# CEC1734_S0_2HW register map
Vendor: Microchip
Registers are 32-bit, read-write, reset 0x0 unless marked. A register's access mark holds for its fields unless they carry their own. Addresses are absolute, and some are shared; only a register's first bit layout is shown; [hi:lo] are bit positions; {n}, {i} and the like mark numbered series; 'fields as' and 'values as' point back to an identical list.

## SPI_MON0
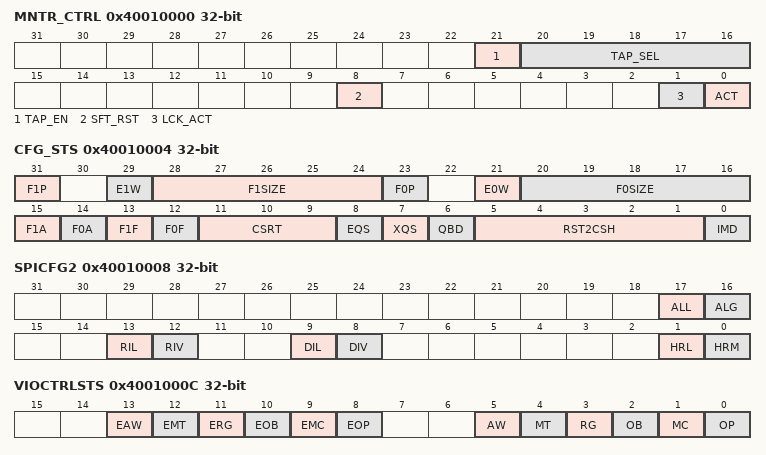
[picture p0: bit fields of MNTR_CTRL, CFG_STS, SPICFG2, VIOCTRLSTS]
0x40010000 MNTR_CTRL
  [21] TAP_EN — CPTR_CLK_TAP_EN enable the delay taps. It is recommended that a customer set the TAP_EN bit to 1, and the TAP_SEL field to 04h.
  [20:16] TAP_SEL — CPTR_CLK_TAP_SEL selects which 0.5ns delay tap to have the capture clock on. 00h = 0 ns delay (or if TAP_EN = 0). 01h = 0.5ns nom delay; +/- 50% 02h = 1.0ns 03h = 1.5ns 04h = 2.0ns etc. 1Fh = 15.5ns
  [8] SFT_RST — Soft Reset. This field is auto cleared by hardware. 1= Soft Reset SPI Monitor, 0 = No Effect
  [1] LCK_ACT — Lock Activate 1= Activate field Locked, 0= Activate field unlocked
  [0] ACT — Activate 1= Activate, 0= De-activate
0x40010004 CFG_STS
  [31] F1P — Flash 1 Present. 0=Not Present, 1=Present
  [29] E1W — Enable Wrap Detection. 0=Disable, 1=Enable
  [28:24] F1SIZE — Flash 1 Size. Flash sizes are expressed in bytes as a power of 2, matching a Flash Get-ID convention. For the most common cases: 17h = 23d => 2^23 = 8MByte 18h = 24d => 2^24 = 16MByte 19h = 25d => 2^25 = 32MByte 1Ah = 26d => 2^26 = 64MByte
  [23] F0P — Flash 0 Present. 0=Not Present, 1=Present
  [21] E0W — Enable Wrap Detection. 0=Disable, 1=Enable.
  [20:16] F0SIZE — Flash 0 Size. Flash sizes are expressed in bytes as a power of 2, matching a Flash Get-ID convention. For the most common cases: 17h = 23d => 2^23 = 8MByte 18h = 24d => 2^24 = 16MByte 19h = 25d => 2^25 = 32MByte 1Ah = 26d => 2^26 = 64MByte
  [15] F1A — Set 3B/4B Address Mode for Flash 1. 0=3B Address Mode, 1=4B Address Mode
  [14] F0A — Set 3B/4B Address Mode for Flash 0. 0=3B Address Mode, 1=4B Address Mode
  [13] F1F — Enable following of Address Mode. (SPI Snooping) for each Flash. 0=Disable, 1=Enable
  [12] F0F — Enable following of Address Mode. (SPI Snooping) for each Flash. 0=Disable, 1=Enable
  [11:9] CSRT — Chip Select Routing. 000 = Both CSn#_In pass directly to CSn# Out, both enabled out. 001 = CS1n_In passes to CS1# Output, but CS0# Output is disabled (floats high). 010 = CS0n_In passes to CS0# Output, but CS1# Output is disabled (floats high). 100 = Swap CS1#/CS0#_In to CS0#/CS1# Out respectively, both enabled out. 101 = CS0n_In passes to CS1# Out, and CS0# Output is disabled (floats high). 110 = CS1n_In passes to CS0# Out, and CS1# Output is disabled (floats high). x11 = CS0n/CS1n Outputs are both disabled (floating high) regardless of inputs.
  [8] EQS — Enable Q-Switch (Isolator) to Host. 0 = Disable, 1 = Enable.
  [7] XQS — Cross-Over Q-Switch status. (BMC->CPU). RO image of Interbus bit which as 1 overrides EQS bit at both SPI buses without changing their states.
  [6] QBD — Quad Bus Disable, 1 = Half Bus Mode, 0 = IO[3:0] are all controlled by EQS.
  [5:1] RST2CSH — RESET# to CS# High Delay. 2^n x 20us, 00h=20us, 1Fh= 1.3sec. IRQ triggers at this point also.
  [0] IMD — Flash Intervention Mode. 0 = Power-Off (POR), 1 = RESET# Pulse
0x40010008 SPICFG2
  [17] ALL — ALG Bit Lock. 0 = Unlocked, 1 = Locked.
  [16] ALG — Hash Algorithm Mode. 0 = SHA-384, 1 = Reserved
  [13] RIL — RIV Bit Lock. 0 = Unlocked, 1 = Locked.
  [12] RIV — Special Region InterVention Mode. If DIV=1 then RIV is ignored. If DIV=0 and RIV=1 then: Reads that are forbidden by the Runtime Region register set are only cancelled by gating off CSn# for that SPI command, and setting the IRQ. No system shutdown results, and subsequent legal Reads are allowed.
  [9] DIL — DIV Bit Lock. 0 = Unlocked, 1 = Locked.
  [8] DIV — Disable Inter Vention. 1 = IRQ-only Mode.
  [1] HRL — HRM Bit Lock. 0 = Unlocked, 1 = Locked.
  [0] HRM — Host Reset Mode. 0 = APn_RESET#, 1 = Pin.
0x4001000C VIOCTRLSTS
  [13] EAW — Enable Address Wrap within a Flash device Interrupt. 0 = Disable, 1 = Enable
  [12] EMT — Enable Timeout in Match Phase Interrupt. 0 = Disable, 1 = Enable
  [11] ERG — Enable Runtime Region R/W Permission Violation Interrupt. 0 = Disable, 1 = Enable
  [10] EOB — Enable Out of Bounds Interrupt. 0 = Disable, 1 = Enable
  [9] EMC — Enable Data Mismatch Violation Interrupt. 0 = Disable, 1 = Enable
  [8] EOP — Enable Opcode Violation Interrupt. 0 = Disable, 1 = Enable
  [5] AW — Address Wrap within a Flash device.
  [4] MT — Timeout in Match Phase
  [3] RG — Runtime Region R/W Permission Violation
  [2] OB — Out of Bounds. Outside all Runtime Regions
  [1] MC — Data Mismatch Violation
  [0] OP — Opcode Violation
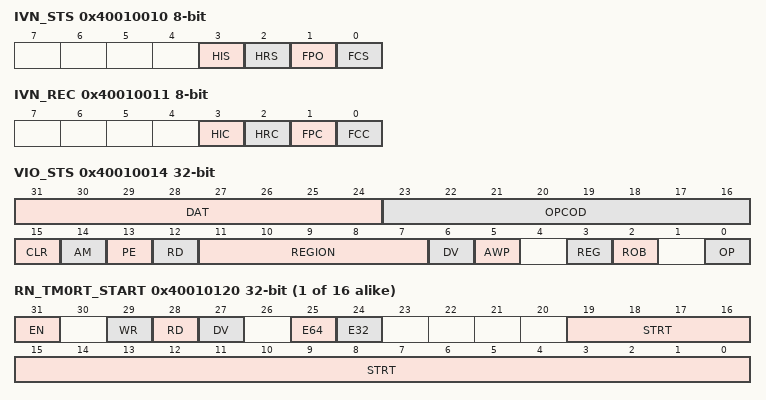
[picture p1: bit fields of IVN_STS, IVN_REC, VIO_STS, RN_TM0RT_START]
0x40010010 IVN_STS 8-bit ro
  [3] HIS — Host held Isolated
  [2] HRS — Host held in Reset
  [1] FPO — Flash Power or RESET# Activated.
  [0] FCS — Flash Chip Selects forced high and bus forced low.
0x40010011 IVN_REC 8-bit wo
  [3] HIC — Write 1 to clear HIS Host held Isolated
  [2] HRC — Write 1 to clear HRS Host held in Reset
  [1] FPC — Write 1 to clear FPO Flash Power or RESET# Activated.
  [0] FCC — Write 1 to clear FCS Flash Chip Selects forced high and bus forced low.
0x40010014 VIO_STS
  [31:24] DAT — SPI Data Byte
  [23:16] OPCOD — Flash Opcode
  [15] CLR — Clear Register RW1C. This bit is auto clearing
  [14] AM — Flash Address Mode
  [13] PE — Killed as a Program or Erase
  [12] RD — Killed as a Read
  [11:7] REGION — Region Number
  [6] DV — Device Number
  [5] AWP — Address Wrap
  [3] REG — Runtime Region Violation
  [2] ROB — Region Failure, Out of Bounds
  [0] OP — Opcode Violation
0x40010018 ERR_ADDR ro
  [31:0] ADDR — Byte address at which the error occurred, within the designated Flash
{0x40010020+4i} FLASH_SET0OP_PRMT{i} (i=0..7)
  [31:0] PRMT — Permit. Each array organized into 8 32-bit registers set per Flash device. 1 = Permit, and if not recognized then ignore. 0 = Kill immediately upon seeing this opcode.
{0x40010040+4i} FLASH_SET0OP_KILLMD{i} (i=0..7)
  [31:0] KILL — Kill. Each array organized into 8 32-bit registers set per Flash device. 1 = If Killed, then kill as a Write: Holding CS# low. 0 = If Killed, then kill as a Read: Force CS# high first.
{0x40010060+4i} FLASH_SET0OP_WPROT{i} (i=0..7)
  [31:0] WPROT — Write Protect. Each array organized into 8 32-bit registers set per Flash device. 1 = Make the corresponding bits RO in Permit and Killmd regs. 0 = Corresponding bits are R/W.
{0x40010080+4i} FLASH_SET0OP_LOCK{i} (i=0..7)
  [31:0] LOCK — Lock. Each array organized into 8 32-bit registers set per Flash device. 1 = Make the corresponding bits RO in Permit and Killmd regs, overriding the Wprot register. Any 1 bit in this register is locked. 0 = Corresponding bits are R/W or RO, as determined by the Wprot register.
{0x400100A0+4i} FLASH_SET1OP_PRMT{i} (i=0..7)
  fields as FLASH_SET0OP_PRMT0
{0x400100C0+4i} FLASH_SET1OP_KILLMD{i} (i=0..7)
  fields as FLASH_SET0OP_KILLMD0
{0x400100E0+4i} FLASH_SET1OP_WPROT{i} (i=0..7)
  fields as FLASH_SET0OP_WPROT0
{0x40010100+4i} FLASH_SET1OP_LOCK{i} (i=0..7)
  fields as FLASH_SET0OP_LOCK0
{0x40010120+8i} RN_TM{i}RT_START (i=0..15)
  [31] EN — Enable Register Pair for Monitoring. 0 = No, 1 = Yes
  [29] WR — Write Allowed for Region. 0 = No, 1 = Yes
  [28] RD — Read Allowed for Region. 0 = No, 1 = Yes
  [27] DV — Flash Device 0 = CS0#, 1 = CS1#.
  [25] E64 — Enable 64KByte Erase opcode for this region. 0 = Disable, 1 = Enable
  [24] E32 — Enable 32KByte Erase opcode for this region. 0 = Disable, 1 = Enable
  [19:0] STRT — A Flash address shifted by 12 (4K byte units). Bottom 12 address bits are 000h
{0x40010124+8i} RN_TM{i}RT_LIMIT (i=0..15)
  [19:0] LMT — Limit Register
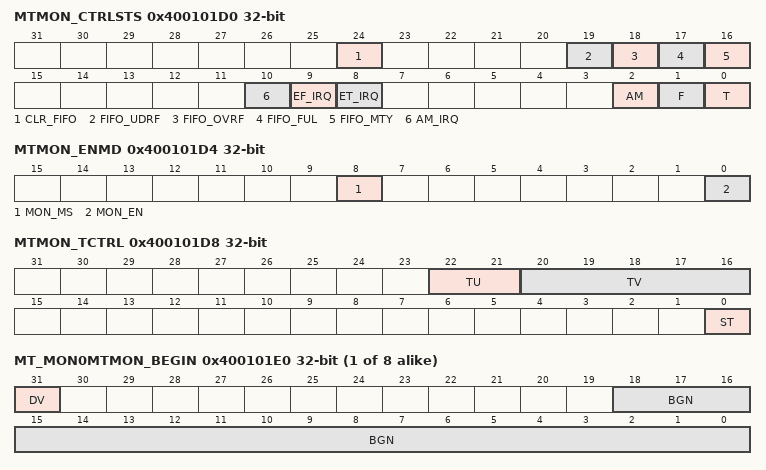
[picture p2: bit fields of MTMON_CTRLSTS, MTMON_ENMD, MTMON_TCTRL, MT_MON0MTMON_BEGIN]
0x400101D0 MTMON_CTRLSTS
  [24] CLR_FIFO — Clear FIFO. This field is autocleared by hardware
  [19] FIFO_UDRF — FIFO Underflow
  [18] FIFO_OVRF — FIFO Overflow
  [17] FIFO_FUL — FIFO Full
  [16] FIFO_MTY — FIFO Empty
  [10] AM_IRQ — Enable 3B/4B Address Mode switch on either Flash Interrupt
  [9] EF_IRQ — Enable First Fetch in any Match region Interrupt
  [8] ET_IRQ — Enable Timeout Interrupt
  [2] AM — Set to 1 on a 3B/4B Address Mode switch on either Flash.
  [1] F — First Fetch in any Match region
  [0] T — Timeout
0x400101D4 MTMON_ENMD
  [8] MON_MS — Match Pattern Source Mode: 0 = SRAM, 1 = Internal Flash.
  [0] MON_EN — Enable Data Matching. 0 = Disabled, 1 = Enabled
0x400101D8 MTMON_TCTRL
  [22:21] TU — Timeout Unit 00 = none (off), 01 = 32ms, 10 = 128ms, 11 = 1sec
  [20:16] TV — Timeout Value 0 to 32
  [0] ST — Start Timeout Counter
{0x400101E0+0xC*i} MT_MON{i}MTMON_BEGIN (i=0..7)
  [31] DV — Flash Device number, applying to both Begin and End fields 0 = CS0#, 1 = CS1#
  [18:0] BGN — The 19 bits of base address within the designated SPI Flash, specifying the last aligned 8K block.
{0x400101E4+0xC*i} MT_MON{i}MTMON_END (i=0..7)
  [18:0] END — The 19 bits of base address within the designated SPI Flash, specifying the last aligned 8K block.
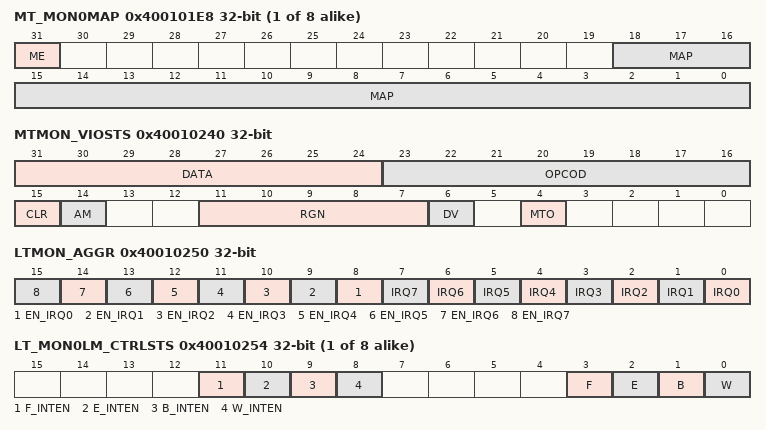
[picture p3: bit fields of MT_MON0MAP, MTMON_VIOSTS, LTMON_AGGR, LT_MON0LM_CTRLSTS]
{0x400101E8+0xC*i} MT_MON{i}MAP (i=0..7)
  [31] ME — Match Enable for individual Region R
  [18:0] MAP — The 19 bits of base address within the designated SPI Flash, specifying the last aligned 8K block.
0x40010240 MTMON_VIOSTS
  [31:24] DATA — SPI Data Byte
  [23:16] OPCOD — Flash Opcode
  [15] CLR — Clear Register RW1C. This bit is auto clearing
  [14] AM — Flash Address Mode 0 = 3-byte, 1 = 4-byte
  [11:7] RGN — Region. This is read-Only bit. Shows which of 8 Match regions [7:0] got the mismatch.
  [6] DV — Device Number. This is read-Only bit. 0 = CS0, 1 = CS1.
  [4] MTO — Match Monitor Timeout. This is read-Only bit.
0x40010244 MTMON_VIOADDR ro
  fields as ERR_ADDR
0x40010250 LTMON_AGGR
  [n+8] EN_IRQ{n} (n=0..7) — Enable Load {n} Interrupt
  [n] IRQ{n} (n=0..7) — Load {n} Interrupt
{0x40010254+0x18*i} LT_MON{i}LM_CTRLSTS (i=0..7)
  [11] F_INTEN — Enable Finalized and result ready Interrupt
  [10] E_INTEN — Enable End Byte seen Interrupt
  [9] B_INTEN — Enable Begin Byte seen Interrupt
  [8] W_INTEN — Enable Waiting Interrupt
  [3] F — Finalized and result ready
  [2] E — End Byte seen
  [1] B — Begin Byte seen
  [0] W — Waiting
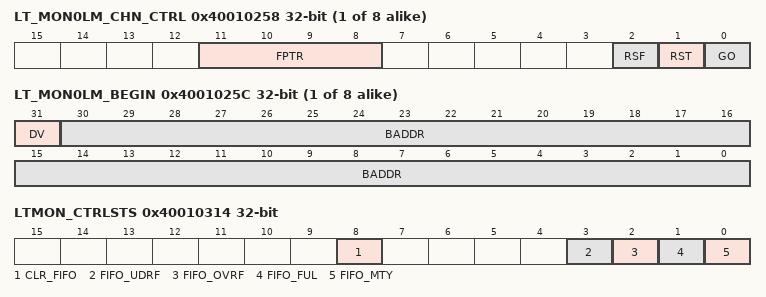
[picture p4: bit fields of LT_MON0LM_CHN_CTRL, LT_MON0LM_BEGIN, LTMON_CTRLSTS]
{0x40010258+0x18*i} LT_MON{i}LM_CHN_CTRL (i=0..7)
  [11:8] FPTR — FPTR: Result FIFO pointer. In 32Bit. Ranges: 0 to 11 for SHA-384 result 0 to 7 for SHA-256 result
  [2] RSF — RSF: Reset just Result FIFO pointer when this bit is set to 1
  [1] RST — RST: Stop and Reset calculation for this channel when set to 1
  [0] GO — GO: Run the Load Monitor for this channel
{0x4001025C+0x18*i} LT_MON{i}LM_BEGIN (i=0..7)
  [31] DV — Flash Device number, applying to both Begin and End fields. 0 = CS0#, 1 = CS1#
  [30:0] BADDR — A byte address within the designated Flash, specifying the first byte of the load image.
{0x40010260+0x18*i} LT_MON{i}LM_END (i=0..7)
  [31:0] EADDR — A byte address within the designated Flash, specifying the last byte of the load image.
{0x40010264+0x18*i} LT_MON{i}LM_COUNT ro (i=0..7)
  [31:0] CNT — A Read-Only count of bytes processed.
{0x40010268+0x18*i} LT_MON{i}LM_DIGEST ro (i=0..7)
  [31:0] DGST — A Read-Only FIFO Portal to Hash digest result. 12 or 8 Dwords depending on algorithm.
0x40010314 LTMON_CTRLSTS
  [8] CLR_FIFO — Clear FIFO
  [3] FIFO_UDRF — FIFO Underflow
  [2] FIFO_OVRF — FIFO Overflow
  [1] FIFO_FUL — FIFO Full
  [0] FIFO_MTY — FIFO Empty
